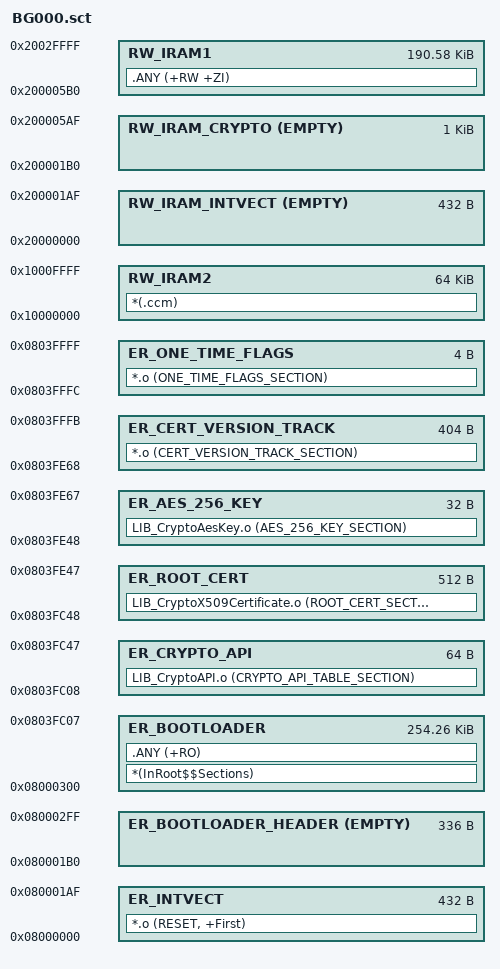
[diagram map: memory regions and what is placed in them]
#! armcc -E 
; *************************************************************
; *** Scatter-Loading Description File generated by uVision ***
; *************************************************************

; *************************************************************
; *** MEMORY HARDWARE DEFINITIONS                           ***
; *************************************************************

#define IRAM_HW_START               0x20000000   // RAM
#define IRAM_HW_LENGTH              0x00030000   // 192K
#define IRAM2_HW_START              0x10000000   // CCM RAM
#define IRAM2_HW_LENGTH             0x00010000   // 64K
#define IFLASH_HW_START             0x08000000   // FLASH
#define IFLASH_HW_LENGTH            0x00200000   // 2M [Just 256K / 0x00040000 available for Boot Loader]

; *************************************************************
; *** COMPONENT LENGTH DEFINITIONS                          ***
; *************************************************************

#define VECTOR_TABLE_LENGTH         432   // bytes. The STM32F4437 has 107 vectors (16 core vectors + 91 user vectors). 107 vectors * 4 bytes = 428 bytes. Pad to 16 byte alignment => 432.
#define COMPONENT_HEADER_LENGTH     336   // bytes. Must match sizeof(tCOMPONENT_HEADER).
#define CRYPTO_API_TABLE_LENGTH      64   // bytes. Must match sizeof(tCRYPTO_API).
#define ONE_TIME_FLAGS_LENGTH         4   // bytes used as one time flags in IFlash.
#define ROOT_CERTIFICATE_LENGTH     512   // bytes.
#define AES_256_KEY_LENGTH           32   // bytes.
#define CERT_VERSION_TRACK_LENGTH   404   // bytes.
#define BOOTLOADER_LENGTH           (0x00040000 - VECTOR_TABLE_LENGTH - COMPONENT_HEADER_LENGTH - CRYPTO_API_TABLE_LENGTH - ONE_TIME_FLAGS_LENGTH - ROOT_CERTIFICATE_LENGTH - AES_256_KEY_LENGTH - CERT_VERSION_TRACK_LENGTH)
#define CRYPTO_RAM_LENGTH          1024
#define GENERAL_RAM_LENGTH          (0x00030000 - CRYPTO_RAM_LENGTH - VECTOR_TABLE_LENGTH)

; *************************************************************
; *** COMPONENT BOUNDARY DEFINITIONS                        ***
; *************************************************************

; --- IFLASH Begin ---

; Interrupt vector table.
#define INTVECT_START               IFLASH_HW_START
#define INTVECT_END                 (INTVECT_START + VECTOR_TABLE_LENGTH - 1)

; Bootstrap code.
#define BOOTLOADER_HEADER           (INTVECT_END + 1)
#define BOOTLOADER_START            (BOOTLOADER_HEADER + COMPONENT_HEADER_LENGTH)
#define BOOTLOADER_END              (BOOTLOADER_START + BOOTLOADER_LENGTH - 1)

; Crypto API.
#define CRYPTO_API_START            (BOOTLOADER_END + 1)
#define CRYPTO_API_END              (CRYPTO_API_START + CRYPTO_API_TABLE_LENGTH - 1)

; Bootstrap certificates and keys.
#define ROOT_CERT_START             (CRYPTO_API_END + 1)
#define ROOT_CERT_END               (ROOT_CERT_START + ROOT_CERTIFICATE_LENGTH - 1)
#define AES_256_KEY_START           (ROOT_CERT_END + 1)
#define AES_256_KEY_END             (AES_256_KEY_START + AES_256_KEY_LENGTH - 1)

; Bootstrap certificate version tracking.
#define CERT_VERSION_TRACK_START    (AES_256_KEY_END + 1)
#define CERT_VERSION_TRACK_END      (CERT_VERSION_TRACK_START + CERT_VERSION_TRACK_LENGTH - 1)

; Bootstrap one time Flash flags.
#define ONE_TIME_FLAGS_START        (CERT_VERSION_TRACK_END + 1)
#define ONE_TIME_FLAGS_END          (ONE_TIME_FLAGS_START + ONE_TIME_FLAGS_LENGTH - 1)

; --- IFLASH End ---

; --- IRAM Begin ---

#define IRAM_INTVECT_START          IRAM_HW_START
#define IRAM_INTVECT_END            (IRAM_INTVECT_START + VECTOR_TABLE_LENGTH - 1)

#define IRAM_CRYPTO_START           (IRAM_INTVECT_END + 1)
#define IRAM_CRYPTO_END             (IRAM_CRYPTO_START + CRYPTO_RAM_LENGTH - 1)

#define IRAM_GENERAL_START          (IRAM_CRYPTO_END + 1)
#define IRAM_GENERAL_END            (IRAM_GENERAL_START + GENERAL_RAM_LENGTH - 1)

; --- IRAM End ---

; *************************************************************
; *** MEMORY REGIONS, BLOCKS and PLACEMENT                  ***
; *************************************************************

LR_INTVECT                 INTVECT_START                           VECTOR_TABLE_LENGTH          { ; load region size_region
  ER_INTVECT                 INTVECT_START                           VECTOR_TABLE_LENGTH        { ; load address = execution address
    *.o (RESET, +First)
  }
}

LR_BOOTLOADER_HEADER       BOOTLOADER_HEADER    ALIGN 4            COMPONENT_HEADER_LENGTH      { ; load region size_region
  ER_BOOTLOADER_HEADER       BOOTLOADER_HEADER    ALIGN 16  EMPTY    COMPONENT_HEADER_LENGTH    { ; load region size_region
  }
}

LR_BOOTLOADER              BOOTLOADER_START     ALIGN 4            BOOTLOADER_LENGTH            { ; load region size_region
  ER_BOOTLOADER              BOOTLOADER_START                        BOOTLOADER_LENGTH          {
    *(InRoot$$Sections)
    .ANY (+RO)
  }
  RW_IRAM_INTVECT            IRAM_INTVECT_START             EMPTY    VECTOR_TABLE_LENGTH        {
  }
  RW_IRAM_CRYPTO             IRAM_CRYPTO_START              EMPTY    CRYPTO_RAM_LENGTH          {
  }
  RW_IRAM1                   IRAM_GENERAL_START                      GENERAL_RAM_LENGTH         { ; RW data
;    FLIN_RAM.o (+RO)
    .ANY (+RW +ZI)
  }
  RW_IRAM2 IRAM2_HW_START IRAM2_HW_LENGTH  {  ; CCM (64K)
    *(.ccm)                          ; Decorate Data by __attribute__ ((section(".ccm")))
  }
}

LR_CRYPTO_API              CRYPTO_API_START                        CRYPTO_API_TABLE_LENGTH      { ; load region size_region
  ER_CRYPTO_API              CRYPTO_API_START                        CRYPTO_API_TABLE_LENGTH    {
    LIB_CryptoAPI.o (CRYPTO_API_TABLE_SECTION)
  }
}

LR_ROOT_CERT               ROOT_CERT_START                         ROOT_CERTIFICATE_LENGTH      { ; load region size_region
  ER_ROOT_CERT               ROOT_CERT_START                         ROOT_CERTIFICATE_LENGTH    {
    LIB_CryptoX509Certificate.o (ROOT_CERT_SECTION)
  }
}

LR_AES_256_KEY             AES_256_KEY_START                       AES_256_KEY_LENGTH           { ; load region size_region
  ER_AES_256_KEY             AES_256_KEY_START                       AES_256_KEY_LENGTH         {
    LIB_CryptoAesKey.o (AES_256_KEY_SECTION)
  }
}

LR_CERT_VERSION_TRACK      CERT_VERSION_TRACK_START                CERT_VERSION_TRACK_LENGTH    { ; load region size_region
  ER_CERT_VERSION_TRACK      CERT_VERSION_TRACK_START                CERT_VERSION_TRACK_LENGTH  {
    *.o (CERT_VERSION_TRACK_SECTION)
  }
}

LR_ONE_TIME_FLAGS          ONE_TIME_FLAGS_START                    ONE_TIME_FLAGS_LENGTH        { ; load region size_region
  ER_ONE_TIME_FLAGS          ONE_TIME_FLAGS_START                    ONE_TIME_FLAGS_LENGTH      {
    *.o (ONE_TIME_FLAGS_SECTION)
  }
}
